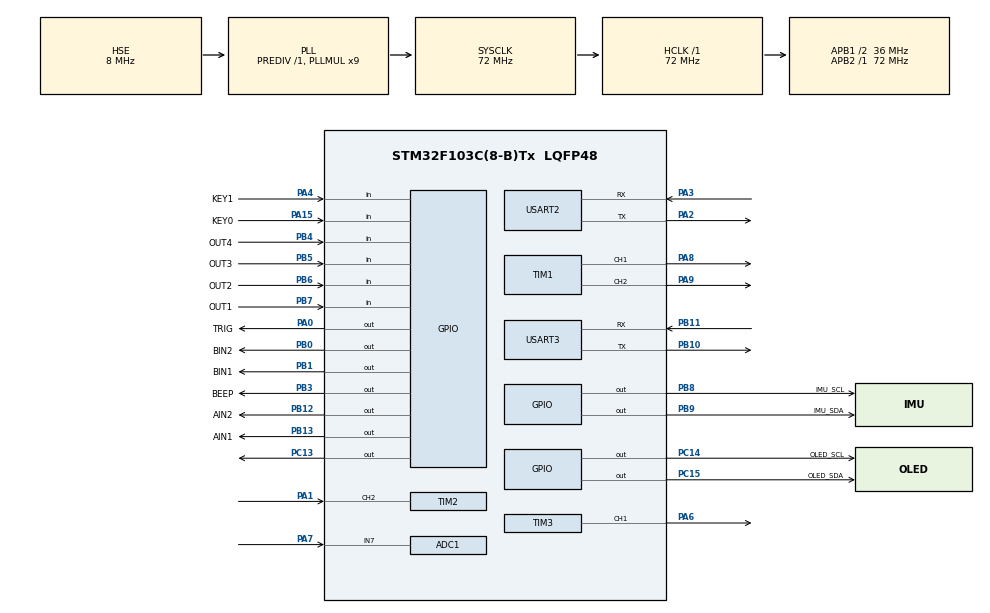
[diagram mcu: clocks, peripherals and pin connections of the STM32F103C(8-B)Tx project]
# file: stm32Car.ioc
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ADC1.Channel-0\#ChannelRegularConversion=ADC_CHANNEL_7
ADC1.NbrOfConversionFlag=1
ADC1.Rank-0\#ChannelRegularConversion=1
ADC1.SamplingTime-0\#ChannelRegularConversion=ADC_SAMPLETIME_1CYCLE_5
ADC1.master=1
FREERTOS.Tasks01=defaultTask,24,128,StartDefaultTask,Default,NULL,Dynamic,NULL,NULL
FREERTOS.configUSE_NEWLIB_REENTRANT=0
Mcu.Family=STM32F1
Mcu.Name=STM32F103C(8-B)Tx
Mcu.Package=LQFP48
NVIC.PriorityGroup=NVIC_PRIORITYGROUP_4
NVIC.TIM1_CC_IRQn=true\:5\:0\:false\:false\:true\:true\:true\:true\:true
NVIC.TIM4_IRQn=true\:15\:0\:false\:false\:true\:false\:false\:true\:true
NVIC.TimeBase=TIM4_IRQn
NVIC.TimeBaseIP=TIM4
NVIC.USART2_IRQn=true\:5\:0\:false\:false\:true\:true\:true\:true\:true
NVIC.USART3_IRQn=true\:5\:0\:false\:false\:true\:true\:true\:true\:true
PA0-WKUP.GPIO_Label=TRIG
PA0-WKUP.GPIO_Speed=GPIO_SPEED_FREQ_HIGH
PA0-WKUP.Signal=GPIO_Output
PA1.Signal=S_TIM2_CH2
PA13.Mode=Serial_Wire
PA13.Signal=SYS_JTMS-SWDIO
PA14.Mode=Serial_Wire
PA14.Signal=SYS_JTCK-SWCLK
PA15.GPIO_Label=KEY0
PA15.GPIO_Mode=GPIO_MODE_INPUT
PA15.GPIO_PuPd=GPIO_PULLDOWN
PA15.Signal=GPIO_Input
PA2.Mode=Asynchronous
PA2.Signal=USART2_TX
PA3.Mode=Asynchronous
PA3.Signal=USART2_RX
PA4.GPIO_Label=KEY1
PA4.GPIO_Mode=GPIO_MODE_INPUT
PA4.GPIO_PuPd=GPIO_PULLDOWN
PA4.Signal=GPIO_Input
PA6.Signal=S_TIM3_CH1
PA7.Signal=ADCx_IN7
PA8.Signal=S_TIM1_CH1
PA9.Signal=S_TIM1_CH2
PB0.GPIO_Label=BIN2
PB0.GPIO_Speed=GPIO_SPEED_FREQ_HIGH
PB0.Signal=GPIO_Output
PB1.GPIO_Label=BIN1
PB1.GPIO_Speed=GPIO_SPEED_FREQ_HIGH
PB1.Signal=GPIO_Output
PB10.Mode=Asynchronous
PB10.Signal=USART3_TX
PB11.Mode=Asynchronous
PB11.Signal=USART3_RX
PB12.GPIO_Label=AIN2
PB12.GPIO_Speed=GPIO_SPEED_FREQ_HIGH
PB12.Signal=GPIO_Output
PB13.GPIO_Label=AIN1
PB13.GPIO_Speed=GPIO_SPEED_FREQ_HIGH
PB13.Signal=GPIO_Output
PB3.GPIO_Label=BEEP
PB3.GPIO_PuPd=GPIO_PULLUP
PB3.GPIO_Speed=GPIO_SPEED_FREQ_HIGH
PB3.Signal=GPIO_Output
PB4.GPIO_Label=OUT4
PB4.Signal=GPIO_Input
PB5.GPIO_Label=OUT3
PB5.Signal=GPIO_Input
PB6.GPIO_Label=OUT2
PB6.Signal=GPIO_Input
PB7.GPIO_Label=OUT1
PB7.Signal=GPIO_Input
PB8.GPIO_Label=IMU_SCL
PB8.GPIO_ModeDefaultOutputPP=GPIO_MODE_OUTPUT_OD
PB8.GPIO_PuPd=GPIO_PULLUP
PB8.GPIO_Speed=GPIO_SPEED_FREQ_HIGH
PB8.Signal=GPIO_Output
PB9.GPIO_Label=IMU_SDA
PB9.GPIO_ModeDefaultOutputPP=GPIO_MODE_OUTPUT_OD
PB9.GPIO_PuPd=GPIO_PULLUP
PB9.GPIO_Speed=GPIO_SPEED_FREQ_HIGH
PB9.Signal=GPIO_Output
PC13-TAMPER-RTC.GPIO_ModeDefaultOutputPP=GPIO_MODE_OUTPUT_PP
PC13-TAMPER-RTC.GPIO_PuPd=GPIO_NOPULL
PC13-TAMPER-RTC.GPIO_Speed=GPIO_SPEED_FREQ_HIGH
PC13-TAMPER-RTC.Signal=GPIO_Output
PC14-OSC32_IN.GPIO_Label=OLED_SCL
PC14-OSC32_IN.GPIO_ModeDefaultOutputPP=GPIO_MODE_OUTPUT_OD
PC14-OSC32_IN.GPIO_PuPd=GPIO_PULLUP
PC14-OSC32_IN.GPIO_Speed=GPIO_SPEED_FREQ_HIGH
PC14-OSC32_IN.PinState=GPIO_PIN_RESET
PC14-OSC32_IN.Signal=GPIO_Output
PC15-OSC32_OUT.GPIO_Label=OLED_SDA
PC15-OSC32_OUT.GPIO_ModeDefaultOutputPP=GPIO_MODE_OUTPUT_OD
PC15-OSC32_OUT.GPIO_PuPd=GPIO_PULLUP
PC15-OSC32_OUT.GPIO_Speed=GPIO_SPEED_FREQ_HIGH
PC15-OSC32_OUT.Signal=GPIO_Output
PD0-OSC_IN.Mode=HSE-External-Oscillator
PD0-OSC_IN.Signal=RCC_OSC_IN
PD1-OSC_OUT.Mode=HSE-External-Oscillator
PD1-OSC_OUT.Signal=RCC_OSC_OUT
ProjectManager.HeapSize=0x200
ProjectManager.StackSize=0x400
ProjectManager.TargetToolchain=MDK-ARM V5.32
RCC.ADCPresc=RCC_ADCPCLK2_DIV6
RCC.AHBFreq_Value=72000000
RCC.APB1CLKDivider=RCC_HCLK_DIV2
RCC.APB1Freq_Value=36000000
RCC.APB1TimFreq_Value=72000000
RCC.APB2Freq_Value=72000000
RCC.APB2TimFreq_Value=72000000
RCC.HCLKFreq_Value=72000000
RCC.PLLMUL=RCC_PLL_MUL9
RCC.PLLSourceVirtual=RCC_PLLSOURCE_HSE
RCC.SYSCLKFreq_VALUE=72000000
RCC.SYSCLKSource=RCC_SYSCLKSOURCE_PLLCLK
RCC.USBFreq_Value=72000000
SH.ADCx_IN7.0=ADC1_IN7,IN7
SH.S_TIM1_CH1.0=TIM1_CH1,Output Compare1 CH1
SH.S_TIM1_CH2.0=TIM1_CH2,Output Compare2 CH2
SH.S_TIM2_CH2.0=TIM2_CH2,Input_Capture2_from_TI2
SH.S_TIM3_CH1.0=TIM3_CH1,PWM Generation1 CH1
TIM1.Channel-Output\ Compare1\ CH1=TIM_CHANNEL_1
TIM1.Channel-Output\ Compare2\ CH2=TIM_CHANNEL_2
TIM2.Channel-Input_Capture2_from_TI2=TIM_CHANNEL_2
TIM3.AutoReloadPreload=TIM_AUTORELOAD_PRELOAD_DISABLE
TIM3.Channel-PWM\ Generation1\ CH1=TIM_CHANNEL_1
TIM3.Period=20000-1
TIM3.Prescaler=72-1
USART2.Parity=PARITY_NONE
USART2.VirtualMode=VM_ASYNC
USART3.VirtualMode=VM_ASYNC
VP_FREERTOS_VS_CMSIS_V2.Mode=CMSIS_V2
VP_SYS_VS_tim4.Mode=TIM4
VP_TIM1_VS_ClockSourceINT.Mode=Internal
VP_TIM2_VS_ClockSourceINT.Mode=Internal
VP_TIM3_VS_ClockSourceINT.Mode=Internal
board=custom

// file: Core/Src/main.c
/* USER CODE BEGIN Header */
/**
  ******************************************************************************
  * @file           : main.c
  * @brief          : Main program body
  ******************************************************************************
  * @attention
  *
  * Copyright (c) 2024 STMicroelectronics.
  * All rights reserved.
  *
  * This software is licensed under terms that can be found in the LICENSE file
  * in the root directory of this software component.
  * If no LICENSE file comes with this software, it is provided AS-IS.
  *
  ******************************************************************************
  */
/* USER CODE END Header */
#include "main.h"
#include "cmsis_os.h"
#include "adc.h"
#include "tim.h"
#include "usart.h"
#include "gpio.h"

void SystemClock_Config(void);
void MX_FREERTOS_Init(void);

int main(void)
{

  /* MCU Configuration--------------------------------------------------------*/

  /* Reset of all peripherals, Initializes the Flash interface and the Systick. */
  HAL_Init();

  /* Configure the system clock */
  SystemClock_Config();

  /* Initialize all configured peripherals */
  MX_GPIO_Init();
  MX_ADC1_Init();
  MX_TIM1_Init();
  MX_TIM2_Init();
  MX_TIM3_Init();
  MX_USART2_UART_Init();
  MX_USART3_UART_Init();

  /* Init scheduler */
  osKernelInitialize();  /* Call init function for freertos objects (in freertos.c) */
  MX_FREERTOS_Init();

  /* Start scheduler */
  osKernelStart();

  /* We should never get here as control is now taken by the scheduler */
  /* Infinite loop */
  while (1)
  {

  }
}

void SystemClock_Config(void)
{
  RCC_OscInitTypeDef RCC_OscInitStruct = {0};
  RCC_ClkInitTypeDef RCC_ClkInitStruct = {0};
  RCC_PeriphCLKInitTypeDef PeriphClkInit = {0};

  /** Initializes the RCC Oscillators according to the specified parameters
  * in the RCC_OscInitTypeDef structure.
  */
  RCC_OscInitStruct.OscillatorType = RCC_OSCILLATORTYPE_HSE;
  RCC_OscInitStruct.HSEState = RCC_HSE_ON;
  RCC_OscInitStruct.HSEPredivValue = RCC_HSE_PREDIV_DIV1;
  RCC_OscInitStruct.HSIState = RCC_HSI_ON;
  RCC_OscInitStruct.PLL.PLLState = RCC_PLL_ON;
  RCC_OscInitStruct.PLL.PLLSource = RCC_PLLSOURCE_HSE;
  RCC_OscInitStruct.PLL.PLLMUL = RCC_PLL_MUL9;
  if (HAL_RCC_OscConfig(&RCC_OscInitStruct) != HAL_OK)
  {
    Error_Handler();
  }

  /** Initializes the CPU, AHB and APB buses clocks
  */
  RCC_ClkInitStruct.ClockType = RCC_CLOCKTYPE_HCLK|RCC_CLOCKTYPE_SYSCLK
                              |RCC_CLOCKTYPE_PCLK1|RCC_CLOCKTYPE_PCLK2;
  RCC_ClkInitStruct.SYSCLKSource = RCC_SYSCLKSOURCE_PLLCLK;
  RCC_ClkInitStruct.AHBCLKDivider = RCC_SYSCLK_DIV1;
  RCC_ClkInitStruct.APB1CLKDivider = RCC_HCLK_DIV2;
  RCC_ClkInitStruct.APB2CLKDivider = RCC_HCLK_DIV1;

  if (HAL_RCC_ClockConfig(&RCC_ClkInitStruct, FLASH_LATENCY_2) != HAL_OK)
  {
    Error_Handler();
  }
  PeriphClkInit.PeriphClockSelection = RCC_PERIPHCLK_ADC;
  PeriphClkInit.AdcClockSelection = RCC_ADCPCLK2_DIV6;
  if (HAL_RCCEx_PeriphCLKConfig(&PeriphClkInit) != HAL_OK)
  {
    Error_Handler();
  }
}

void HAL_TIM_PeriodElapsedCallback(TIM_HandleTypeDef *htim)
{
  if (htim->Instance == TIM4) {
    HAL_IncTick();
  }
}

void Error_Handler(void)
{
  __disable_irq();
  while (1)
  {
  }
}

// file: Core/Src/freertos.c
/* USER CODE BEGIN Header */
/**
  ******************************************************************************
  * File Name          : freertos.c
  * Description        : Code for freertos applications
  ******************************************************************************
  * @attention
  *
  * Copyright (c) 2024 STMicroelectronics.
  * All rights reserved.
  *
  * This software is licensed under terms that can be found in the LICENSE file
  * in the root directory of this software component.
  * If no LICENSE file comes with this software, it is provided AS-IS.
  *
  ******************************************************************************
  */
/* USER CODE END Header */

#include "FreeRTOS.h"
#include "task.h"
#include "main.h"
#include "cmsis_os.h"

/* Definitions for defaultTask */
osThreadId_t defaultTaskHandle;
const osThreadAttr_t defaultTask_attributes = {
  .name = "defaultTask",
  .stack_size = 128 * 4,
  .priority = (osPriority_t) osPriorityNormal,
};

void StartDefaultTask(void *argument);

void MX_FREERTOS_Init(void); /* (MISRA C 2004 rule 8.1) */

void MX_FREERTOS_Init(void) {

  /* Create the thread(s) */
  /* creation of defaultTask */
  defaultTaskHandle = osThreadNew(StartDefaultTask, NULL, &defaultTask_attributes);

}

void StartDefaultTask(void *argument)
{
  /* USER CODE BEGIN StartDefaultTask */
  /* Infinite loop */
  for(;;)
  {
    HAL_GPIO_TogglePin(GPIOC, GPIO_PIN_13);
    osDelay(500);
  }
  /* USER CODE END StartDefaultTask */
}
